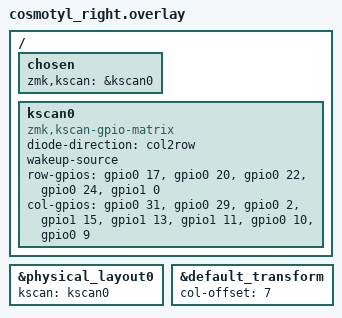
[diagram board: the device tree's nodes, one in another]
#include "cosmotyl.dtsi"

/ {
    chosen {
        zmk,kscan = &kscan0;
    };

    kscan0: kscan0 {
        compatible = "zmk,kscan-gpio-matrix";
        diode-direction = "col2row";
        wakeup-source;

        /* RIGHT ROWS: R0 R1 R2 R3 R4 */
        row-gpios =
            <&gpio0 17 (GPIO_ACTIVE_HIGH | GPIO_PULL_DOWN)>,
            <&gpio0 20 (GPIO_ACTIVE_HIGH | GPIO_PULL_DOWN)>,
            <&gpio0 22 (GPIO_ACTIVE_HIGH | GPIO_PULL_DOWN)>,
            <&gpio0 24 (GPIO_ACTIVE_HIGH | GPIO_PULL_DOWN)>,
            <&gpio1  0 (GPIO_ACTIVE_HIGH | GPIO_PULL_DOWN)>;

        /* RIGHT COLUMNS: C0 C1 C2 C3 C4 C5 C6 C7 */
        col-gpios =
            <&gpio0 31 GPIO_ACTIVE_HIGH>,
            <&gpio0 29 GPIO_ACTIVE_HIGH>,
            <&gpio0  2 GPIO_ACTIVE_HIGH>,
            <&gpio1 15 GPIO_ACTIVE_HIGH>,
            <&gpio1 13 GPIO_ACTIVE_HIGH>,
            <&gpio1 11 GPIO_ACTIVE_HIGH>,
            <&gpio0 10 GPIO_ACTIVE_HIGH>,
            <&gpio0  9 GPIO_ACTIVE_HIGH>;
    };
};

&physical_layout0 {
    kscan = <&kscan0>;
};

&default_transform {
    col-offset = <7>;
};
